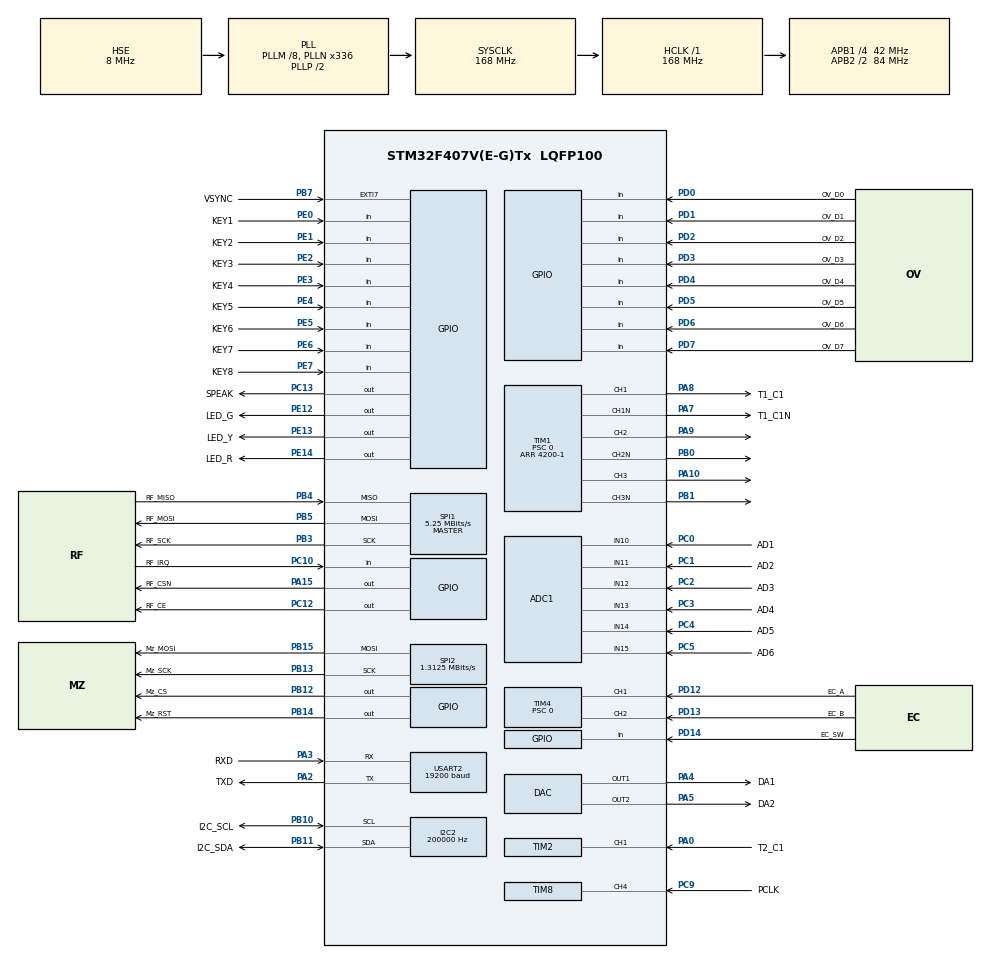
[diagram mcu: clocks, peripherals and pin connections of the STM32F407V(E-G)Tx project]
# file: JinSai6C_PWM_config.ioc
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ADC1.Channel-0\#ChannelRegularConversion=ADC_CHANNEL_10
ADC1.Channel-1\#ChannelRegularConversion=ADC_CHANNEL_11
ADC1.Channel-2\#ChannelRegularConversion=ADC_CHANNEL_12
ADC1.Channel-3\#ChannelRegularConversion=ADC_CHANNEL_13
ADC1.Channel-4\#ChannelRegularConversion=ADC_CHANNEL_14
ADC1.Channel-5\#ChannelRegularConversion=ADC_CHANNEL_15
ADC1.ContinuousConvMode=ENABLE
ADC1.DMAContinuousRequests=ENABLE
ADC1.EOCSelection=ADC_EOC_SEQ_CONV
ADC1.ExternalTrigConv=ADC_EXTERNALTRIGCONV_T3_TRGO
ADC1.NbrOfConversion=6
ADC1.NbrOfConversionFlag=1
ADC1.Rank-0\#ChannelRegularConversion=1
ADC1.Rank-1\#ChannelRegularConversion=2
ADC1.Rank-2\#ChannelRegularConversion=3
ADC1.Rank-3\#ChannelRegularConversion=4
ADC1.Rank-4\#ChannelRegularConversion=5
ADC1.Rank-5\#ChannelRegularConversion=6
ADC1.SamplingTime-0\#ChannelRegularConversion=ADC_SAMPLETIME_15CYCLES
ADC1.SamplingTime-1\#ChannelRegularConversion=ADC_SAMPLETIME_15CYCLES
ADC1.SamplingTime-2\#ChannelRegularConversion=ADC_SAMPLETIME_15CYCLES
ADC1.SamplingTime-3\#ChannelRegularConversion=ADC_SAMPLETIME_15CYCLES
ADC1.SamplingTime-4\#ChannelRegularConversion=ADC_SAMPLETIME_15CYCLES
ADC1.SamplingTime-5\#ChannelRegularConversion=ADC_SAMPLETIME_15CYCLES
ADC1.ScanConvMode=ENABLE
ADC1.master=1
DAC.DAC_OutputBuffer=DAC_OUTPUTBUFFER_DISABLE
Dma.ADC1.0.Direction=DMA_PERIPH_TO_MEMORY
Dma.ADC1.0.FIFOMode=DMA_FIFOMODE_DISABLE
Dma.ADC1.0.Instance=DMA2_Stream0
Dma.ADC1.0.MemDataAlignment=DMA_MDATAALIGN_WORD
Dma.ADC1.0.MemInc=DMA_MINC_ENABLE
Dma.ADC1.0.Mode=DMA_CIRCULAR
Dma.ADC1.0.PeriphDataAlignment=DMA_PDATAALIGN_WORD
Dma.ADC1.0.PeriphInc=DMA_PINC_DISABLE
Dma.ADC1.0.Priority=DMA_PRIORITY_HIGH
Dma.Request0=ADC1
Dma.Request1=TIM8_CH4/TRIG/COM
Dma.TIM8_CH4/TRIG/COM.1.Direction=DMA_PERIPH_TO_MEMORY
Dma.TIM8_CH4/TRIG/COM.1.FIFOMode=DMA_FIFOMODE_DISABLE
Dma.TIM8_CH4/TRIG/COM.1.Instance=DMA2_Stream7
Dma.TIM8_CH4/TRIG/COM.1.MemDataAlignment=DMA_MDATAALIGN_BYTE
Dma.TIM8_CH4/TRIG/COM.1.MemInc=DMA_MINC_ENABLE
Dma.TIM8_CH4/TRIG/COM.1.Mode=DMA_CIRCULAR
Dma.TIM8_CH4/TRIG/COM.1.PeriphDataAlignment=DMA_PDATAALIGN_BYTE
Dma.TIM8_CH4/TRIG/COM.1.PeriphInc=DMA_PINC_DISABLE
Dma.TIM8_CH4/TRIG/COM.1.Priority=DMA_PRIORITY_HIGH
I2C2.ClockSpeed=200000
I2C2.I2C_Mode=I2C_Fast
Mcu.Family=STM32F4
Mcu.Name=STM32F407V(E-G)Tx
Mcu.Package=LQFP100
NVIC.ADC_IRQn=true\:0\:0\:false\:false\:true\:true\:true\:true
NVIC.DMA2_Stream0_IRQn=true\:0\:0\:false\:false\:true\:false\:true\:true
NVIC.DMA2_Stream7_IRQn=true\:0\:0\:false\:false\:true\:false\:true\:true
NVIC.EXTI9_5_IRQn=true\:1\:0\:true\:false\:true\:true\:true\:true
NVIC.PriorityGroup=NVIC_PRIORITYGROUP_4
NVIC.RTC_Alarm_IRQn=true\:3\:0\:true\:false\:true\:true\:true\:true
NVIC.TIM1_TRG_COM_TIM11_IRQn=true\:0\:0\:false\:false\:true\:true\:true\:true
NVIC.TIM1_UP_TIM10_IRQn=true\:0\:0\:false\:false\:true\:true\:true\:true
NVIC.TIM3_IRQn=true\:1\:0\:true\:false\:true\:true\:true\:true
NVIC.USART2_IRQn=true\:2\:0\:true\:false\:true\:true\:true\:true
PA0-WKUP.GPIO_Label=T2_C1
PA0-WKUP.GPIO_PuPd=GPIO_PULLUP
PA0-WKUP.Signal=S_TIM2_CH1_ETR
PA10.Signal=S_TIM1_CH3
PA13.Mode=Serial_Wire
PA13.Signal=SYS_JTMS-SWDIO
PA14.Mode=Serial_Wire
PA14.Signal=SYS_JTCK-SWCLK
PA15.GPIO_Label=RF_CSN
PA15.GPIO_Speed=GPIO_SPEED_FREQ_HIGH
PA15.PinState=GPIO_PIN_SET
PA15.Signal=GPIO_Output
PA2.GPIO_Label=TXD
PA2.GPIO_Speed=GPIO_SPEED_FREQ_MEDIUM
PA2.Mode=Asynchronous
PA2.Signal=USART2_TX
PA3.GPIO_Label=RXD
PA3.GPIO_Speed=GPIO_SPEED_FREQ_MEDIUM
PA3.Mode=Asynchronous
PA3.Signal=USART2_RX
PA4.GPIO_Label=DA1
PA4.Signal=COMP_DAC1_group
PA5.GPIO_Label=DA2
PA5.Signal=COMP_DAC2_group
PA7.GPIO_Label=T1_C1N
PA7.Mode=PWM Generation1 CH1 CH1N
PA7.Signal=TIM1_CH1N
PA8.GPIO_Label=T1_C1
PA8.Signal=S_TIM1_CH1
PA9.Signal=S_TIM1_CH2
PB0.Mode=PWM Generation2 CH2 CH2N
PB0.Signal=TIM1_CH2N
PB1.Mode=PWM Generation3 CH3 CH3N
PB1.Signal=TIM1_CH3N
PB10.GPIO_Label=I2C_SCL
PB10.GPIO_Pu=GPIO_PULLUP
PB10.GPIO_Speed=GPIO_SPEED_FREQ_MEDIUM
PB10.Mode=I2C
PB10.Signal=I2C2_SCL
PB11.GPIO_Label=I2C_SDA
PB11.GPIO_Pu=GPIO_PULLUP
PB11.GPIO_Speed=GPIO_SPEED_FREQ_MEDIUM
PB11.Mode=I2C
PB11.Signal=I2C2_SDA
PB12.GPIO_Label=Mz_CS
PB12.Signal=GPIO_Output
PB13.GPIO_Label=Mz_SCK
PB13.GPIO_Speed=GPIO_SPEED_FREQ_MEDIUM
PB13.Mode=TX_Only_Simplex_Unidirect_Master
PB13.Signal=SPI2_SCK
PB14.GPIO_Label=Mz_RST
PB14.Signal=GPIO_Output
PB15.GPIO_Label=Mz_MOSI
PB15.GPIO_Speed=GPIO_SPEED_FREQ_MEDIUM
PB15.Mode=TX_Only_Simplex_Unidirect_Master
PB15.Signal=SPI2_MOSI
PB3.GPIO_Label=RF_SCK
PB3.GPIO_Speed=GPIO_SPEED_FREQ_HIGH
PB3.Mode=Full_Duplex_Master
PB3.Signal=SPI1_SCK
PB4.GPIO_Label=RF_MISO
PB4.GPIO_Speed=GPIO_SPEED_FREQ_HIGH
PB4.Mode=Full_Duplex_Master
PB4.Signal=SPI1_MISO
PB5.GPIO_Label=RF_MOSI
PB5.GPIO_Speed=GPIO_SPEED_FREQ_HIGH
PB5.Mode=Full_Duplex_Master
PB5.Signal=SPI1_MOSI
PB7.GPIO_Label=VSYNC
PB7.GPIO_ModeDefaultEXTI=GPIO_MODE_IT_FALLING
PB7.GPIO_PuPd=GPIO_PULLDOWN
PB7.Signal=GPXTI7
PC0.GPIO_Label=AD1
PC0.Signal=ADCx_IN10
PC1.GPIO_Label=AD2
PC1.Signal=ADCx_IN11
PC10.GPIO_Label=RF_IRQ
PC10.GPIO_PuPd=GPIO_PULLUP
PC10.Signal=GPIO_Input
PC12.GPIO_Label=RF_CE
PC12.GPIO_Speed=GPIO_SPEED_FREQ_HIGH
PC12.Signal=GPIO_Output
PC13-ANTI_TAMP.GPIO_Label=SPEAK
PC13-ANTI_TAMP.Signal=GPIO_Output
PC14-OSC32_IN.Mode=LSE-External-Oscillator
PC14-OSC32_IN.Signal=RCC_OSC32_IN
PC15-OSC32_OUT.Mode=LSE-External-Oscillator
PC15-OSC32_OUT.Signal=RCC_OSC32_OUT
PC2.GPIO_Label=AD3
PC2.Signal=ADCx_IN12
PC3.GPIO_Label=AD4
PC3.Signal=ADCx_IN13
PC4.GPIO_Label=AD5
PC4.Signal=ADCx_IN14
PC5.GPIO_Label=AD6
PC5.Signal=ADCx_IN15
PC9.GPIO_Label=PCLK
PC9.GPIO_Speed=GPIO_SPEED_FREQ_VERY_HIGH
PC9.Signal=S_TIM8_CH4
PD0.GPIO_Label=OV_D0
PD0.GPIO_PuPd=GPIO_PULLDOWN
PD0.Signal=GPIO_Input
PD1.GPIO_Label=OV_D1
PD1.GPIO_PuPd=GPIO_PULLDOWN
PD1.Signal=GPIO_Input
PD12.GPIO_Label=EC_A
PD12.GPIO_PuPd=GPIO_PULLUP
PD12.Signal=S_TIM4_CH1
PD13.GPIO_Label=EC_B
PD13.GPIO_PuPd=GPIO_PULLUP
PD13.Signal=S_TIM4_CH2
PD14.GPIO_Label=EC_SW
PD14.GPIO_PuPd=GPIO_PULLUP
PD14.Signal=GPIO_Input
PD2.GPIO_Label=OV_D2
PD2.GPIO_PuPd=GPIO_PULLDOWN
PD2.Signal=GPIO_Input
PD3.GPIO_Label=OV_D3
PD3.GPIO_PuPd=GPIO_PULLDOWN
PD3.Signal=GPIO_Input
PD4.GPIO_Label=OV_D4
PD4.GPIO_PuPd=GPIO_PULLDOWN
PD4.Signal=GPIO_Input
PD5.GPIO_Label=OV_D5
PD5.GPIO_PuPd=GPIO_PULLDOWN
PD5.Signal=GPIO_Input
PD6.GPIO_Label=OV_D6
PD6.GPIO_PuPd=GPIO_PULLDOWN
PD6.Signal=GPIO_Input
PD7.GPIO_Label=OV_D7
PD7.GPIO_PuPd=GPIO_PULLDOWN
PD7.Signal=GPIO_Input
PE0.GPIO_Label=KEY1
PE0.GPIO_PuPd=GPIO_PULLUP
PE0.Signal=GPIO_Input
PE1.GPIO_Label=KEY2
PE1.GPIO_PuPd=GPIO_PULLUP
PE1.Signal=GPIO_Input
PE12.GPIO_Label=LED_G
PE12.Signal=GPIO_Output
PE13.GPIO_Label=LED_Y
PE13.Signal=GPIO_Output
PE14.GPIO_Label=LED_R
PE14.Signal=GPIO_Output
PE2.GPIO_Label=KEY3
PE2.GPIO_PuPd=GPIO_PULLUP
PE2.Signal=GPIO_Input
PE3.GPIO_Label=KEY4
PE3.GPIO_PuPd=GPIO_PULLUP
PE3.Signal=GPIO_Input
PE4.GPIO_Label=KEY5
PE4.GPIO_PuPd=GPIO_PULLUP
PE4.Signal=GPIO_Input
PE5.GPIO_Label=KEY6
PE5.GPIO_PuPd=GPIO_PULLUP
PE5.Signal=GPIO_Input
PE6.GPIO_Label=KEY7
PE6.GPIO_PuPd=GPIO_PULLUP
PE6.Signal=GPIO_Input
PE7.GPIO_Label=KEY8
PE7.GPIO_PuPd=GPIO_PULLUP
PE7.Signal=GPIO_Input
PH0-OSC_IN.Mode=HSE-External-Oscillator
PH0-OSC_IN.Signal=RCC_OSC_IN
PH1-OSC_OUT.Mode=HSE-External-Oscillator
PH1-OSC_OUT.Signal=RCC_OSC_OUT
ProjectManager.HeapSize=0x200
ProjectManager.StackSize=0x400
ProjectManager.TargetToolchain=MDK-ARM V5.32
RCC.48MHZClocksFreq_Value=84000000
RCC.AHBFreq_Value=168000000
RCC.APB1CLKDivider=RCC_HCLK_DIV4
RCC.APB1Freq_Value=42000000
RCC.APB1TimFreq_Value=84000000
RCC.APB2CLKDivider=RCC_HCLK_DIV2
RCC.APB2Freq_Value=84000000
RCC.APB2TimFreq_Value=168000000
RCC.CortexFreq_Value=168000000
RCC.HCLKFreq_Value=168000000
RCC.HSE_VALUE=8000000
RCC.HSI_VALUE=16000000
RCC.PLLM=8
RCC.PLLN=336
RCC.PLLSourceVirtual=RCC_PLLSOURCE_HSE
RCC.RCC_RTC_Clock_Source=RCC_RTCCLKSOURCE_LSE
RCC.RCC_RTC_Clock_SourceVirtual=RCC_RTCCLKSOURCE_LSE
RCC.SYSCLKFreq_VALUE=168000000
RCC.SYSCLKSource=RCC_SYSCLKSOURCE_PLLCLK
RCC.VCOOutputFreq_Value=336000000
RTC.Alarm=RTC_ALARM_A
RTC.AlarmMaskDateWeekDay=RTC_ALARMMASK_DATEWEEKDAY
RTC.AlarmMaskHours=RTC_ALARMMASK_HOURS
RTC.AlarmSubSecondMask=RTC_ALARMSUBSECONDMASK_NONE
RTC.Date=1
RTC.Format=RTC_FORMAT_BIN
RTC.Hours=12
RTC.Minutes=59
RTC.Minutes_A=59
RTC.Month=RTC_MONTH_JANUARY
RTC.Seconds=30
RTC.Seconds_A=59
RTC.SubSeconds_A=51
RTC.WeekDay=RTC_WEEKDAY_TUESDAY
RTC.Year=19
SH.ADCx_IN10.0=ADC1_IN10,IN10
SH.ADCx_IN11.0=ADC1_IN11,IN11
SH.ADCx_IN12.0=ADC1_IN12,IN12
SH.ADCx_IN13.0=ADC1_IN13,IN13
SH.ADCx_IN14.0=ADC1_IN14,IN14
SH.ADCx_IN15.0=ADC1_IN15,IN15
SH.COMP_DAC1_group.0=DAC_OUT1,DAC_OUT1
SH.COMP_DAC2_group.0=DAC_OUT2,DAC_OUT2
SH.S_TIM1_CH1.0=TIM1_CH1,PWM Generation1 CH1 CH1N
SH.S_TIM1_CH2.0=TIM1_CH2,PWM Generation2 CH2 CH2N
SH.S_TIM1_CH3.0=TIM1_CH3,PWM Generation3 CH3 CH3N
SH.S_TIM2_CH1_ETR.0=TIM2_CH1,PWM_Input_1
SH.S_TIM4_CH1.0=TIM4_CH1,Encoder_Interface
SH.S_TIM4_CH2.0=TIM4_CH2,Encoder_Interface
SH.S_TIM8_CH4.0=TIM8_CH4,Input_Capture4_from_TI4
SPI1.BaudRatePrescaler=SPI_BAUDRATEPRESCALER_16
SPI1.CalculateBaudRate=5.25 MBits/s
SPI1.Direction=SPI_DIRECTION_2LINES
SPI1.Mode=SPI_MODE_MASTER
SPI1.VirtualType=VM_MASTER
SPI2.BaudRatePrescaler=SPI_BAUDRATEPRESCALER_32
SPI2.CLKPhase=SPI_PHASE_2EDGE
SPI2.CLKPolarity=SPI_POLARITY_HIGH
SPI2.CalculateBaudRate=1.3125 MBits/s
SPI2.Direction=SPI_DIRECTION_2LINES
SPI2.Mode=SPI_MODE_MASTER
SPI2.VirtualType=VM_MASTER
TIM1.Channel-PWM\ Generation1\ CH1\ CH1N=TIM_CHANNEL_1
TIM1.Channel-PWM\ Generation2\ CH2\ CH2N=TIM_CHANNEL_2
TIM1.Channel-PWM\ Generation3\ CH3\ CH3N=TIM_CHANNEL_3
TIM1.Channel-PWM\ Generation4\ No\ Output=TIM_CHANNEL_4
TIM1.CounterMode=TIM_COUNTERMODE_CENTERALIGNED1
TIM1.DeadTime=150
TIM1.Period=4200-1
TIM1.Prescaler=0
TIM1.Pulse-PWM\ Generation1\ CH1\ CH1N=4200
TIM1.Pulse-PWM\ Generation4\ No\ Output=500
TIM1.RepetitionCounter=1
TIM1.TIM_MasterOutputTrigger=TIM_TRGO_UPDATE
TIM1.TIM_MasterSlaveMode=TIM_MASTERSLAVEMODE_DISABLE
TIM2.Period=0xffffffff
TIM2.Prescaler=83
TIM3.AutoReloadPreload=TIM_AUTORELOAD_PRELOAD_ENABLE
TIM3.CounterMode=TIM_COUNTERMODE_CENTERALIGNED1
TIM3.Period=1000
TIM3.Prescaler=0
TIM3.TIM_MasterOutputTrigger=TIM_TRGO_UPDATE
TIM4.EncoderMode=TIM_ENCODERMODE_TI12
TIM4.Period=8400-1
TIM4.Prescaler=0
TIM8.Channel-Input_Capture4_from_TI4=TIM_CHANNEL_4
TIM8.Period=0xffff
TIM8.Prescaler=167
USART2.BaudRate=19200
USART2.VirtualMode=VM_ASYNC
VP_ADC1_TempSens_Input.Mode=IN-TempSens
VP_ADC1_Vbat_Input.Mode=IN-Vbat
VP_ADC1_Vref_Input.Mode=IN-Vrefint
VP_RTC_VS_RTC_Activate.Mode=RTC_Enabled
VP_RTC_VS_RTC_Alarm_A_Intern.Mode=Alarm A
VP_RTC_VS_RTC_Calendar.Mode=RTC_Calendar
VP_TIM1_VS_ClockSourceINT.Mode=Internal
VP_TIM1_VS_no_output4.Mode=PWM Generation4 No Output
VP_TIM2_VS_ClockSourceINT.Mode=Internal
VP_TIM3_VS_ClockSourceINT.Mode=Internal
VP_TIM3_VS_ClockSourceITR.Mode=TriggerSource_ITR0
VP_TIM3_VS_ControllerModeTrigger.Mode=Trigger Mode
VP_TIM8_VS_ClockSourceINT.Mode=Internal
board=custom

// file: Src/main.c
/* USER CODE BEGIN Header */
/**
  ******************************************************************************
  * @file           : main.c
  * @brief          : Main program body
  ******************************************************************************
  * @attention
  *
  * <h2><center>&copy; Copyright (c) 2025 STMicroelectronics.
  * All rights reserved.</center></h2>
  *
  * This software component is licensed by ST under BSD 3-Clause license,
  * the "License"; You may not use this file except in compliance with the
  * License. You may obtain a copy of the License at:
  *                        opensource.org/licenses/BSD-3-Clause
  *
  ******************************************************************************
  */
/* USER CODE END Header */
#include "main.h"

/* USER CODE BEGIN Includes */

// include GMP headers
#include <gmp_core.h>

/* USER CODE END Includes */

ADC_HandleTypeDef hadc1;
DMA_HandleTypeDef hdma_adc1;

DAC_HandleTypeDef hdac;

I2C_HandleTypeDef hi2c2;

RTC_HandleTypeDef hrtc;

SPI_HandleTypeDef hspi1;
SPI_HandleTypeDef hspi2;

TIM_HandleTypeDef htim1;
TIM_HandleTypeDef htim2;
TIM_HandleTypeDef htim3;
TIM_HandleTypeDef htim4;
TIM_HandleTypeDef htim8;
DMA_HandleTypeDef hdma_tim8_ch4_trig_com;

UART_HandleTypeDef huart2;

void SystemClock_Config(void);
static void MX_GPIO_Init(void);
static void MX_DMA_Init(void);
static void MX_RTC_Init(void);
static void MX_SPI2_Init(void);
static void MX_ADC1_Init(void);
static void MX_DAC_Init(void);
static void MX_I2C2_Init(void);
static void MX_USART2_UART_Init(void);
static void MX_TIM1_Init(void);
static void MX_TIM2_Init(void);
static void MX_TIM4_Init(void);
static void MX_SPI1_Init(void);
static void MX_TIM8_Init(void);
static void MX_TIM3_Init(void);

int main(void)
{

  /* MCU Configuration--------------------------------------------------------*/

  /* Reset of all peripherals, Initializes the Flash interface and the Systick. */
  HAL_Init();

  /* Configure the system clock */
  SystemClock_Config();

  /* Initialize all configured peripherals */
  MX_GPIO_Init();
  MX_DMA_Init();
  MX_RTC_Init();
  MX_SPI2_Init();
  MX_ADC1_Init();
  MX_DAC_Init();
  MX_I2C2_Init();
  MX_USART2_UART_Init();
  MX_TIM1_Init();
  MX_TIM2_Init();
  MX_TIM4_Init();
  MX_SPI1_Init();
  MX_TIM8_Init();
  MX_TIM3_Init();
  /* USER CODE BEGIN 2 */

	HAL_GPIO_WritePin(LED_R_GPIO_Port, LED_R_Pin, GPIO_PIN_SET);

	// Controller Starup at the last position
	gmp_base_init();
  /* USER CODE END 2 */

  /* Infinite loop */
  /* USER CODE BEGIN WHILE */

  while (1)
  {

		gmp_base_loop();
    /* USER CODE END WHILE */

  }
}

void SystemClock_Config(void)
{
  RCC_OscInitTypeDef RCC_OscInitStruct = {0};
  RCC_ClkInitTypeDef RCC_ClkInitStruct = {0};

  /** Configure the main internal regulator output voltage
  */
  __HAL_RCC_PWR_CLK_ENABLE();
  __HAL_PWR_VOLTAGESCALING_CONFIG(PWR_REGULATOR_VOLTAGE_SCALE1);

  /** Initializes the RCC Oscillators according to the specified parameters
  * in the RCC_OscInitTypeDef structure.
  */
  RCC_OscInitStruct.OscillatorType = RCC_OSCILLATORTYPE_HSE|RCC_OSCILLATORTYPE_LSE;
  RCC_OscInitStruct.HSEState = RCC_HSE_ON;
  RCC_OscInitStruct.LSEState = RCC_LSE_ON;
  RCC_OscInitStruct.PLL.PLLState = RCC_PLL_ON;
  RCC_OscInitStruct.PLL.PLLSource = RCC_PLLSOURCE_HSE;
  RCC_OscInitStruct.PLL.PLLM = 8;
  RCC_OscInitStruct.PLL.PLLN = 336;
  RCC_OscInitStruct.PLL.PLLP = RCC_PLLP_DIV2;
  RCC_OscInitStruct.PLL.PLLQ = 4;
  if (HAL_RCC_OscConfig(&RCC_OscInitStruct) != HAL_OK)
  {
    Error_Handler();
  }

  /** Initializes the CPU, AHB and APB buses clocks
  */
  RCC_ClkInitStruct.ClockType = RCC_CLOCKTYPE_HCLK|RCC_CLOCKTYPE_SYSCLK
                              |RCC_CLOCKTYPE_PCLK1|RCC_CLOCKTYPE_PCLK2;
  RCC_ClkInitStruct.SYSCLKSource = RCC_SYSCLKSOURCE_PLLCLK;
  RCC_ClkInitStruct.AHBCLKDivider = RCC_SYSCLK_DIV1;
  RCC_ClkInitStruct.APB1CLKDivider = RCC_HCLK_DIV4;
  RCC_ClkInitStruct.APB2CLKDivider = RCC_HCLK_DIV2;

  if (HAL_RCC_ClockConfig(&RCC_ClkInitStruct, FLASH_LATENCY_5) != HAL_OK)
  {
    Error_Handler();
  }
}

static void MX_ADC1_Init(void)
{

  ADC_ChannelConfTypeDef sConfig = {0};

  /** Configure the global features of the ADC (Clock, Resolution, Data Alignment and number of conversion)
  */
  hadc1.Instance = ADC1;
  hadc1.Init.ClockPrescaler = ADC_CLOCK_SYNC_PCLK_DIV4;
  hadc1.Init.Resolution = ADC_RESOLUTION_12B;
  hadc1.Init.ScanConvMode = ENABLE;
  hadc1.Init.ContinuousConvMode = ENABLE;
  hadc1.Init.DiscontinuousConvMode = DISABLE;
  hadc1.Init.ExternalTrigConvEdge = ADC_EXTERNALTRIGCONVEDGE_RISING;
  hadc1.Init.ExternalTrigConv = ADC_EXTERNALTRIGCONV_T3_TRGO;
  hadc1.Init.DataAlign = ADC_DATAALIGN_RIGHT;
  hadc1.Init.NbrOfConversion = 6;
  hadc1.Init.DMAContinuousRequests = ENABLE;
  hadc1.Init.EOCSelection = ADC_EOC_SEQ_CONV;
  if (HAL_ADC_Init(&hadc1) != HAL_OK)
  {
    Error_Handler();
  }

  /** Configure for the selected ADC regular channel its corresponding rank in the sequencer and its sample time.
  */
  sConfig.Channel = ADC_CHANNEL_10;
  sConfig.Rank = 1;
  sConfig.SamplingTime = ADC_SAMPLETIME_15CYCLES;
  if (HAL_ADC_ConfigChannel(&hadc1, &sConfig) != HAL_OK)
  {
    Error_Handler();
  }

  /** Configure for the selected ADC regular channel its corresponding rank in the sequencer and its sample time.
  */
  sConfig.Channel = ADC_CHANNEL_11;
  sConfig.Rank = 2;
  if (HAL_ADC_ConfigChannel(&hadc1, &sConfig) != HAL_OK)
  {
    Error_Handler();
  }

  /** Configure for the selected ADC regular channel its corresponding rank in the sequencer and its sample time.
  */
  sConfig.Channel = ADC_CHANNEL_12;
  sConfig.Rank = 3;
  if (HAL_ADC_ConfigChannel(&hadc1, &sConfig) != HAL_OK)
  {
    Error_Handler();
  }

  /** Configure for the selected ADC regular channel its corresponding rank in the sequencer and its sample time.
  */
  sConfig.Channel = ADC_CHANNEL_13;
  sConfig.Rank = 4;
  if (HAL_ADC_ConfigChannel(&hadc1, &sConfig) != HAL_OK)
  {
    Error_Handler();
  }

  /** Configure for the selected ADC regular channel its corresponding rank in the sequencer and its sample time.
  */
  sConfig.Channel = ADC_CHANNEL_14;
  sConfig.Rank = 5;
  if (HAL_ADC_ConfigChannel(&hadc1, &sConfig) != HAL_OK)
  {
    Error_Handler();
  }

  /** Configure for the selected ADC regular channel its corresponding rank in the sequencer and its sample time.
  */
  sConfig.Channel = ADC_CHANNEL_15;
  sConfig.Rank = 6;
  if (HAL_ADC_ConfigChannel(&hadc1, &sConfig) != HAL_OK)
  {
    Error_Handler();
  }

}

static void MX_DAC_Init(void)
{

  DAC_ChannelConfTypeDef sConfig = {0};

  /** DAC Initialization
  */
  hdac.Instance = DAC;
  if (HAL_DAC_Init(&hdac) != HAL_OK)
  {
    Error_Handler();
  }

  /** DAC channel OUT1 config
  */
  sConfig.DAC_Trigger = DAC_TRIGGER_NONE;
  sConfig.DAC_OutputBuffer = DAC_OUTPUTBUFFER_DISABLE;
  if (HAL_DAC_ConfigChannel(&hdac, &sConfig, DAC_CHANNEL_1) != HAL_OK)
  {
    Error_Handler();
  }

  /** DAC channel OUT2 config
  */
  sConfig.DAC_OutputBuffer = DAC_OUTPUTBUFFER_ENABLE;
  if (HAL_DAC_ConfigChannel(&hdac, &sConfig, DAC_CHANNEL_2) != HAL_OK)
  {
    Error_Handler();
  }

}

static void MX_I2C2_Init(void)
{

  hi2c2.Instance = I2C2;
  hi2c2.Init.ClockSpeed = 200000;
  hi2c2.Init.DutyCycle = I2C_DUTYCYCLE_2;
  hi2c2.Init.OwnAddress1 = 0;
  hi2c2.Init.AddressingMode = I2C_ADDRESSINGMODE_7BIT;
  hi2c2.Init.DualAddressMode = I2C_DUALADDRESS_DISABLE;
  hi2c2.Init.OwnAddress2 = 0;
  hi2c2.Init.GeneralCallMode = I2C_GENERALCALL_DISABLE;
  hi2c2.Init.NoStretchMode = I2C_NOSTRETCH_DISABLE;
  if (HAL_I2C_Init(&hi2c2) != HAL_OK)
  {
    Error_Handler();
  }

}

static void MX_RTC_Init(void)
{

  RTC_TimeTypeDef sTime = {0};
  RTC_DateTypeDef sDate = {0};
  RTC_AlarmTypeDef sAlarm = {0};

  /** Initialize RTC Only
  */
  hrtc.Instance = RTC;
  hrtc.Init.HourFormat = RTC_HOURFORMAT_24;
  hrtc.Init.AsynchPrediv = 127;
  hrtc.Init.SynchPrediv = 255;
  hrtc.Init.OutPut = RTC_OUTPUT_DISABLE;
  hrtc.Init.OutPutPolarity = RTC_OUTPUT_POLARITY_HIGH;
  hrtc.Init.OutPutType = RTC_OUTPUT_TYPE_OPENDRAIN;
  if (HAL_RTC_Init(&hrtc) != HAL_OK)
  {
    Error_Handler();
  }

  /** Initialize RTC and set the Time and Date
  */
  sTime.Hours = 12;
  sTime.Minutes = 59;
  sTime.Seconds = 30;
  sTime.DayLightSaving = RTC_DAYLIGHTSAVING_NONE;
  sTime.StoreOperation = RTC_STOREOPERATION_RESET;
  if (HAL_RTC_SetTime(&hrtc, &sTime, RTC_FORMAT_BIN) != HAL_OK)
  {
    Error_Handler();
  }
  sDate.WeekDay = RTC_WEEKDAY_TUESDAY;
  sDate.Month = RTC_MONTH_JANUARY;
  sDate.Date = 1;
  sDate.Year = 19;

  if (HAL_RTC_SetDate(&hrtc, &sDate, RTC_FORMAT_BIN) != HAL_OK)
  {
    Error_Handler();
  }

  /** Enable the Alarm A
  */
  sAlarm.AlarmTime.Hours = 0;
  sAlarm.AlarmTime.Minutes = 59;
  sAlarm.AlarmTime.Seconds = 59;
  sAlarm.AlarmTime.SubSeconds = 51;
  sAlarm.AlarmTime.DayLightSaving = RTC_DAYLIGHTSAVING_NONE;
  sAlarm.AlarmTime.StoreOperation = RTC_STOREOPERATION_RESET;
  sAlarm.AlarmMask = RTC_ALARMMASK_DATEWEEKDAY|RTC_ALARMMASK_HOURS;
  sAlarm.AlarmSubSecondMask = RTC_ALARMSUBSECONDMASK_NONE;
  sAlarm.AlarmDateWeekDaySel = RTC_ALARMDATEWEEKDAYSEL_DATE;
  sAlarm.AlarmDateWeekDay = 1;
  sAlarm.Alarm = RTC_ALARM_A;
  if (HAL_RTC_SetAlarm_IT(&hrtc, &sAlarm, RTC_FORMAT_BIN) != HAL_OK)
  {
    Error_Handler();
  }

}

static void MX_SPI1_Init(void)
{

  /* SPI1 parameter configuration*/
  hspi1.Instance = SPI1;
  hspi1.Init.Mode = SPI_MODE_MASTER;
  hspi1.Init.Direction = SPI_DIRECTION_2LINES;
  hspi1.Init.DataSize = SPI_DATASIZE_8BIT;
  hspi1.Init.CLKPolarity = SPI_POLARITY_LOW;
  hspi1.Init.CLKPhase = SPI_PHASE_1EDGE;
  hspi1.Init.NSS = SPI_NSS_SOFT;
  hspi1.Init.BaudRatePrescaler = SPI_BAUDRATEPRESCALER_16;
  hspi1.Init.FirstBit = SPI_FIRSTBIT_MSB;
  hspi1.Init.TIMode = SPI_TIMODE_DISABLE;
  hspi1.Init.CRCCalculation = SPI_CRCCALCULATION_DISABLE;
  hspi1.Init.CRCPolynomial = 10;
  if (HAL_SPI_Init(&hspi1) != HAL_OK)
  {
    Error_Handler();
  }

}

static void MX_SPI2_Init(void)
{

  /* SPI2 parameter configuration*/
  hspi2.Instance = SPI2;
  hspi2.Init.Mode = SPI_MODE_MASTER;
  hspi2.Init.Direction = SPI_DIRECTION_2LINES;
  hspi2.Init.DataSize = SPI_DATASIZE_8BIT;
  hspi2.Init.CLKPolarity = SPI_POLARITY_HIGH;
  hspi2.Init.CLKPhase = SPI_PHASE_2EDGE;
  hspi2.Init.NSS = SPI_NSS_SOFT;
  hspi2.Init.BaudRatePrescaler = SPI_BAUDRATEPRESCALER_32;
  hspi2.Init.FirstBit = SPI_FIRSTBIT_MSB;
  hspi2.Init.TIMode = SPI_TIMODE_DISABLE;
  hspi2.Init.CRCCalculation = SPI_CRCCALCULATION_DISABLE;
  hspi2.Init.CRCPolynomial = 10;
  if (HAL_SPI_Init(&hspi2) != HAL_OK)
  {
    Error_Handler();
  }

}

static void MX_TIM1_Init(void)
{

  TIM_ClockConfigTypeDef sClockSourceConfig = {0};
  TIM_MasterConfigTypeDef sMasterConfig = {0};
  TIM_OC_InitTypeDef sConfigOC = {0};
  TIM_BreakDeadTimeConfigTypeDef sBreakDeadTimeConfig = {0};

  htim1.Instance = TIM1;
  htim1.Init.Prescaler = 0;
  htim1.Init.CounterMode = TIM_COUNTERMODE_CENTERALIGNED1;
  htim1.Init.Period = 4200-1;
  htim1.Init.ClockDivision = TIM_CLOCKDIVISION_DIV1;
  htim1.Init.RepetitionCounter = 1;
  htim1.Init.AutoReloadPreload = TIM_AUTORELOAD_PRELOAD_DISABLE;
  if (HAL_TIM_Base_Init(&htim1) != HAL_OK)
  {
    Error_Handler();
  }
  sClockSourceConfig.ClockSource = TIM_CLOCKSOURCE_INTERNAL;
  if (HAL_TIM_ConfigClockSource(&htim1, &sClockSourceConfig) != HAL_OK)
  {
    Error_Handler();
  }
  if (HAL_TIM_PWM_Init(&htim1) != HAL_OK)
  {
    Error_Handler();
  }
  sMasterConfig.MasterOutputTrigger = TIM_TRGO_UPDATE;
  sMasterConfig.MasterSlaveMode = TIM_MASTERSLAVEMODE_DISABLE;
  if (HAL_TIMEx_MasterConfigSynchronization(&htim1, &sMasterConfig) != HAL_OK)
  {
    Error_Handler();
  }
  sConfigOC.OCMode = TIM_OCMODE_PWM1;
  sConfigOC.Pulse = 4200;
  sConfigOC.OCPolarity = TIM_OCPOLARITY_HIGH;
  sConfigOC.OCNPolarity = TIM_OCNPOLARITY_HIGH;
  sConfigOC.OCFastMode = TIM_OCFAST_DISABLE;
  sConfigOC.OCIdleState = TIM_OCIDLESTATE_RESET;
  sConfigOC.OCNIdleState = TIM_OCNIDLESTATE_RESET;
  if (HAL_TIM_PWM_ConfigChannel(&htim1, &sConfigOC, TIM_CHANNEL_1) != HAL_OK)
  {
    Error_Handler();
  }
  sConfigOC.Pulse = 0;
  if (HAL_TIM_PWM_ConfigChannel(&htim1, &sConfigOC, TIM_CHANNEL_2) != HAL_OK)
  {
    Error_Handler();
  }
  if (HAL_TIM_PWM_ConfigChannel(&htim1, &sConfigOC, TIM_CHANNEL_3) != HAL_OK)
  {
    Error_Handler();
  }
  sConfigOC.Pulse = 500;
  if (HAL_TIM_PWM_ConfigChannel(&htim1, &sConfigOC, TIM_CHANNEL_4) != HAL_OK)
  {
    Error_Handler();
  }
  sBreakDeadTimeConfig.OffStateRunMode = TIM_OSSR_DISABLE;
  sBreakDeadTimeConfig.OffStateIDLEMode = TIM_OSSI_DISABLE;
  sBreakDeadTimeConfig.LockLevel = TIM_LOCKLEVEL_OFF;
  sBreakDeadTimeConfig.DeadTime = 150;
  sBreakDeadTimeConfig.BreakState = TIM_BREAK_DISABLE;
  sBreakDeadTimeConfig.BreakPolarity = TIM_BREAKPOLARITY_HIGH;
  sBreakDeadTimeConfig.AutomaticOutput = TIM_AUTOMATICOUTPUT_DISABLE;
  if (HAL_TIMEx_ConfigBreakDeadTime(&htim1, &sBreakDeadTimeConfig) != HAL_OK)
  {
    Error_Handler();
  }
  HAL_TIM_MspPostInit(&htim1);

}

static void MX_TIM2_Init(void)
{

  TIM_ClockConfigTypeDef sClockSourceConfig = {0};
  TIM_SlaveConfigTypeDef sSlaveConfig = {0};
  TIM_IC_InitTypeDef sConfigIC = {0};
  TIM_MasterConfigTypeDef sMasterConfig = {0};

  htim2.Instance = TIM2;
  htim2.Init.Prescaler = 83;
  htim2.Init.CounterMode = TIM_COUNTERMODE_UP;
  htim2.Init.Period = 0xffffffff;
  htim2.Init.ClockDivision = TIM_CLOCKDIVISION_DIV1;
  htim2.Init.AutoReloadPreload = TIM_AUTORELOAD_PRELOAD_DISABLE;
  if (HAL_TIM_Base_Init(&htim2) != HAL_OK)
  {
    Error_Handler();
  }
  sClockSourceConfig.ClockSource = TIM_CLOCKSOURCE_INTERNAL;
  if (HAL_TIM_ConfigClockSource(&htim2, &sClockSourceConfig) != HAL_OK)
  {
    Error_Handler();
  }
  if (HAL_TIM_IC_Init(&htim2) != HAL_OK)
  {
    Error_Handler();
  }
  sSlaveConfig.SlaveMode = TIM_SLAVEMODE_RESET;
  sSlaveConfig.InputTrigger = TIM_TS_TI1FP1;
  sSlaveConfig.TriggerPolarity = TIM_INPUTCHANNELPOLARITY_RISING;
  sSlaveConfig.TriggerPrescaler = TIM_ICPSC_DIV1;
  sSlaveConfig.TriggerFilter = 0;
  if (HAL_TIM_SlaveConfigSynchro(&htim2, &sSlaveConfig) != HAL_OK)
  {
    Error_Handler();
  }
  sConfigIC.ICPolarity = TIM_INPUTCHANNELPOLARITY_RISING;
  sConfigIC.ICSelection = TIM_ICSELECTION_DIRECTTI;
  sConfigIC.ICPrescaler = TIM_ICPSC_DIV1;
  sConfigIC.ICFilter = 0;
  if (HAL_TIM_IC_ConfigChannel(&htim2, &sConfigIC, TIM_CHANNEL_1) != HAL_OK)
  {
    Error_Handler();
  }
  sConfigIC.ICPolarity = TIM_INPUTCHANNELPOLARITY_FALLING;
  sConfigIC.ICSelection = TIM_ICSELECTION_INDIRECTTI;
  if (HAL_TIM_IC_ConfigChannel(&htim2, &sConfigIC, TIM_CHANNEL_2) != HAL_OK)
  {
    Error_Handler();
  }
  sMasterConfig.MasterOutputTrigger = TIM_TRGO_RESET;
  sMasterConfig.MasterSlaveMode = TIM_MASTERSLAVEMODE_DISABLE;
  if (HAL_TIMEx_MasterConfigSynchronization(&htim2, &sMasterConfig) != HAL_OK)
  {
    Error_Handler();
  }

}

static void MX_TIM3_Init(void)
{

  TIM_ClockConfigTypeDef sClockSourceConfig = {0};
  TIM_SlaveConfigTypeDef sSlaveConfig = {0};
  TIM_MasterConfigTypeDef sMasterConfig = {0};

  htim3.Instance = TIM3;
  htim3.Init.Prescaler = 0;
  htim3.Init.CounterMode = TIM_COUNTERMODE_CENTERALIGNED1;
  htim3.Init.Period = 1000;
  htim3.Init.ClockDivision = TIM_CLOCKDIVISION_DIV1;
  htim3.Init.AutoReloadPreload = TIM_AUTORELOAD_PRELOAD_ENABLE;
  if (HAL_TIM_Base_Init(&htim3) != HAL_OK)
  {
    Error_Handler();
  }
  sClockSourceConfig.ClockSource = TIM_CLOCKSOURCE_INTERNAL;
  if (HAL_TIM_ConfigClockSource(&htim3, &sClockSourceConfig) != HAL_OK)
  {
    Error_Handler();
  }
  sSlaveConfig.SlaveMode = TIM_SLAVEMODE_TRIGGER;
  sSlaveConfig.InputTrigger = TIM_TS_ITR0;
  if (HAL_TIM_SlaveConfigSynchro(&htim3, &sSlaveConfig) != HAL_OK)
  {
    Error_Handler();
  }
  sMasterConfig.MasterOutputTrigger = TIM_TRGO_UPDATE;
  sMasterConfig.MasterSlaveMode = TIM_MASTERSLAVEMODE_DISABLE;
  if (HAL_TIMEx_MasterConfigSynchronization(&htim3, &sMasterConfig) != HAL_OK)
  {
    Error_Handler();
  }

}

static void MX_TIM4_Init(void)
{

  TIM_Encoder_InitTypeDef sConfig = {0};
  TIM_MasterConfigTypeDef sMasterConfig = {0};

  htim4.Instance = TIM4;
  htim4.Init.Prescaler = 0;
  htim4.Init.CounterMode = TIM_COUNTERMODE_UP;
  htim4.Init.Period = 8400-1;
  htim4.Init.ClockDivision = TIM_CLOCKDIVISION_DIV1;
  htim4.Init.AutoReloadPreload = TIM_AUTORELOAD_PRELOAD_DISABLE;
  sConfig.EncoderMode = TIM_ENCODERMODE_TI12;
  sConfig.IC1Polarity = TIM_ICPOLARITY_RISING;
  sConfig.IC1Selection = TIM_ICSELECTION_DIRECTTI;
  sConfig.IC1Prescaler = TIM_ICPSC_DIV1;
  sConfig.IC1Filter = 0;
  sConfig.IC2Polarity = TIM_ICPOLARITY_RISING;
  sConfig.IC2Selection = TIM_ICSELECTION_DIRECTTI;
  sConfig.IC2Prescaler = TIM_ICPSC_DIV1;
  sConfig.IC2Filter = 0;
  if (HAL_TIM_Encoder_Init(&htim4, &sConfig) != HAL_OK)
  {
    Error_Handler();
  }
  sMasterConfig.MasterOutputTrigger = TIM_TRGO_RESET;
  sMasterConfig.MasterSlaveMode = TIM_MASTERSLAVEMODE_DISABLE;
  if (HAL_TIMEx_MasterConfigSynchronization(&htim4, &sMasterConfig) != HAL_OK)
  {
    Error_Handler();
  }

}

static void MX_TIM8_Init(void)
{

  TIM_ClockConfigTypeDef sClockSourceConfig = {0};
  TIM_MasterConfigTypeDef sMasterConfig = {0};
  TIM_IC_InitTypeDef sConfigIC = {0};

  htim8.Instance = TIM8;
  htim8.Init.Prescaler = 167;
  htim8.Init.CounterMode = TIM_COUNTERMODE_UP;
  htim8.Init.Period = 0xffff;
  htim8.Init.ClockDivision = TIM_CLOCKDIVISION_DIV1;
  htim8.Init.RepetitionCounter = 0;
  htim8.Init.AutoReloadPreload = TIM_AUTORELOAD_PRELOAD_DISABLE;
  if (HAL_TIM_Base_Init(&htim8) != HAL_OK)
  {
    Error_Handler();
  }
  sClockSourceConfig.ClockSource = TIM_CLOCKSOURCE_INTERNAL;
  if (HAL_TIM_ConfigClockSource(&htim8, &sClockSourceConfig) != HAL_OK)
  {
    Error_Handler();
  }
  if (HAL_TIM_IC_Init(&htim8) != HAL_OK)
  {
    Error_Handler();
  }
  sMasterConfig.MasterOutputTrigger = TIM_TRGO_RESET;
  sMasterConfig.MasterSlaveMode = TIM_MASTERSLAVEMODE_DISABLE;
  if (HAL_TIMEx_MasterConfigSynchronization(&htim8, &sMasterConfig) != HAL_OK)
  {
    Error_Handler();
  }
  sConfigIC.ICPolarity = TIM_INPUTCHANNELPOLARITY_RISING;
  sConfigIC.ICSelection = TIM_ICSELECTION_DIRECTTI;
  sConfigIC.ICPrescaler = TIM_ICPSC_DIV1;
  sConfigIC.ICFilter = 0;
  if (HAL_TIM_IC_ConfigChannel(&htim8, &sConfigIC, TIM_CHANNEL_4) != HAL_OK)
  {
    Error_Handler();
  }

}

static void MX_USART2_UART_Init(void)
{

  huart2.Instance = USART2;
  huart2.Init.BaudRate = 19200;
  huart2.Init.WordLength = UART_WORDLENGTH_8B;
  huart2.Init.StopBits = UART_STOPBITS_1;
  huart2.Init.Parity = UART_PARITY_NONE;
  huart2.Init.Mode = UART_MODE_TX_RX;
  huart2.Init.HwFlowCtl = UART_HWCONTROL_NONE;
  huart2.Init.OverSampling = UART_OVERSAMPLING_16;
  if (HAL_UART_Init(&huart2) != HAL_OK)
  {
    Error_Handler();
  }

}

static void MX_DMA_Init(void)
{

  /* DMA controller clock enable */
  __HAL_RCC_DMA2_CLK_ENABLE();

  /* DMA interrupt init */
  /* DMA2_Stream0_IRQn interrupt configuration */
  HAL_NVIC_SetPriority(DMA2_Stream0_IRQn, 0, 0);
  HAL_NVIC_EnableIRQ(DMA2_Stream0_IRQn);
  /* DMA2_Stream7_IRQn interrupt configuration */
  HAL_NVIC_SetPriority(DMA2_Stream7_IRQn, 0, 0);
  HAL_NVIC_EnableIRQ(DMA2_Stream7_IRQn);

}

static void MX_GPIO_Init(void)
{
  GPIO_InitTypeDef GPIO_InitStruct = {0};

  /* GPIO Ports Clock Enable */
  __HAL_RCC_GPIOE_CLK_ENABLE();
  __HAL_RCC_GPIOC_CLK_ENABLE();
  __HAL_RCC_GPIOH_CLK_ENABLE();
  __HAL_RCC_GPIOA_CLK_ENABLE();
  __HAL_RCC_GPIOB_CLK_ENABLE();
  __HAL_RCC_GPIOD_CLK_ENABLE();

  /*Configure GPIO pin Output Level */
  HAL_GPIO_WritePin(GPIOC, SPEAK_Pin|RF_CE_Pin, GPIO_PIN_RESET);

  /*Configure GPIO pin Output Level */
  HAL_GPIO_WritePin(GPIOE, LED_G_Pin|LED_Y_Pin|LED_R_Pin, GPIO_PIN_RESET);

  /*Configure GPIO pin Output Level */
  HAL_GPIO_WritePin(GPIOB, Mz_CS_Pin|Mz_RST_Pin, GPIO_PIN_RESET);

  /*Configure GPIO pin Output Level */
  HAL_GPIO_WritePin(RF_CSN_GPIO_Port, RF_CSN_Pin, GPIO_PIN_SET);

  /*Configure GPIO pins : KEY3_Pin KEY4_Pin KEY5_Pin KEY6_Pin
                           KEY7_Pin KEY8_Pin KEY1_Pin KEY2_Pin */
  GPIO_InitStruct.Pin = KEY3_Pin|KEY4_Pin|KEY5_Pin|KEY6_Pin
                          |KEY7_Pin|KEY8_Pin|KEY1_Pin|KEY2_Pin;
  GPIO_InitStruct.Mode = GPIO_MODE_INPUT;
  GPIO_InitStruct.Pull = GPIO_PULLUP;
  HAL_GPIO_Init(GPIOE, &GPIO_InitStruct);

  /*Configure GPIO pin : SPEAK_Pin */
  GPIO_InitStruct.Pin = SPEAK_Pin;
  GPIO_InitStruct.Mode = GPIO_MODE_OUTPUT_PP;
  GPIO_InitStruct.Pull = GPIO_NOPULL;
  GPIO_InitStruct.Speed = GPIO_SPEED_FREQ_LOW;
  HAL_GPIO_Init(SPEAK_GPIO_Port, &GPIO_InitStruct);

  /*Configure GPIO pins : LED_G_Pin LED_Y_Pin LED_R_Pin */
  GPIO_InitStruct.Pin = LED_G_Pin|LED_Y_Pin|LED_R_Pin;
  GPIO_InitStruct.Mode = GPIO_MODE_OUTPUT_PP;
  GPIO_InitStruct.Pull = GPIO_NOPULL;
  GPIO_InitStruct.Speed = GPIO_SPEED_FREQ_LOW;
  HAL_GPIO_Init(GPIOE, &GPIO_InitStruct);

  /*Configure GPIO pins : Mz_CS_Pin Mz_RST_Pin */
  GPIO_InitStruct.Pin = Mz_CS_Pin|Mz_RST_Pin;
  GPIO_InitStruct.Mode = GPIO_MODE_OUTPUT_PP;
  GPIO_InitStruct.Pull = GPIO_NOPULL;
  GPIO_InitStruct.Speed = GPIO_SPEED_FREQ_LOW;
  HAL_GPIO_Init(GPIOB, &GPIO_InitStruct);

  /*Configure GPIO pin : EC_SW_Pin */
  GPIO_InitStruct.Pin = EC_SW_Pin;
  GPIO_InitStruct.Mode = GPIO_MODE_INPUT;
  GPIO_InitStruct.Pull = GPIO_PULLUP;
  HAL_GPIO_Init(EC_SW_GPIO_Port, &GPIO_InitStruct);

  /*Configure GPIO pin : RF_CSN_Pin */
  GPIO_InitStruct.Pin = RF_CSN_Pin;
  GPIO_InitStruct.Mode = GPIO_MODE_OUTPUT_PP;
  GPIO_InitStruct.Pull = GPIO_NOPULL;
  GPIO_InitStruct.Speed = GPIO_SPEED_FREQ_HIGH;
  HAL_GPIO_Init(RF_CSN_GPIO_Port, &GPIO_InitStruct);

  /*Configure GPIO pin : RF_IRQ_Pin */
  GPIO_InitStruct.Pin = RF_IRQ_Pin;
  GPIO_InitStruct.Mode = GPIO_MODE_INPUT;
  GPIO_InitStruct.Pull = GPIO_PULLUP;
  HAL_GPIO_Init(RF_IRQ_GPIO_Port, &GPIO_InitStruct);

  /*Configure GPIO pin : RF_CE_Pin */
  GPIO_InitStruct.Pin = RF_CE_Pin;
  GPIO_InitStruct.Mode = GPIO_MODE_OUTPUT_PP;
  GPIO_InitStruct.Pull = GPIO_NOPULL;
  GPIO_InitStruct.Speed = GPIO_SPEED_FREQ_HIGH;
  HAL_GPIO_Init(RF_CE_GPIO_Port, &GPIO_InitStruct);

  /*Configure GPIO pins : OV_D0_Pin OV_D1_Pin OV_D2_Pin OV_D3_Pin
                           OV_D4_Pin OV_D5_Pin OV_D6_Pin OV_D7_Pin */
  GPIO_InitStruct.Pin = OV_D0_Pin|OV_D1_Pin|OV_D2_Pin|OV_D3_Pin
                          |OV_D4_Pin|OV_D5_Pin|OV_D6_Pin|OV_D7_Pin;
  GPIO_InitStruct.Mode = GPIO_MODE_INPUT;
  GPIO_InitStruct.Pull = GPIO_PULLDOWN;
  HAL_GPIO_Init(GPIOD, &GPIO_InitStruct);

  /*Configure GPIO pin : VSYNC_Pin */
  GPIO_InitStruct.Pin = VSYNC_Pin;
  GPIO_InitStruct.Mode = GPIO_MODE_IT_FALLING;
  GPIO_InitStruct.Pull = GPIO_PULLDOWN;
  HAL_GPIO_Init(VSYNC_GPIO_Port, &GPIO_InitStruct);

  /* EXTI interrupt init*/
  HAL_NVIC_SetPriority(EXTI9_5_IRQn, 1, 0);
  HAL_NVIC_EnableIRQ(EXTI9_5_IRQn);

}

void Error_Handler(void)
{
}
